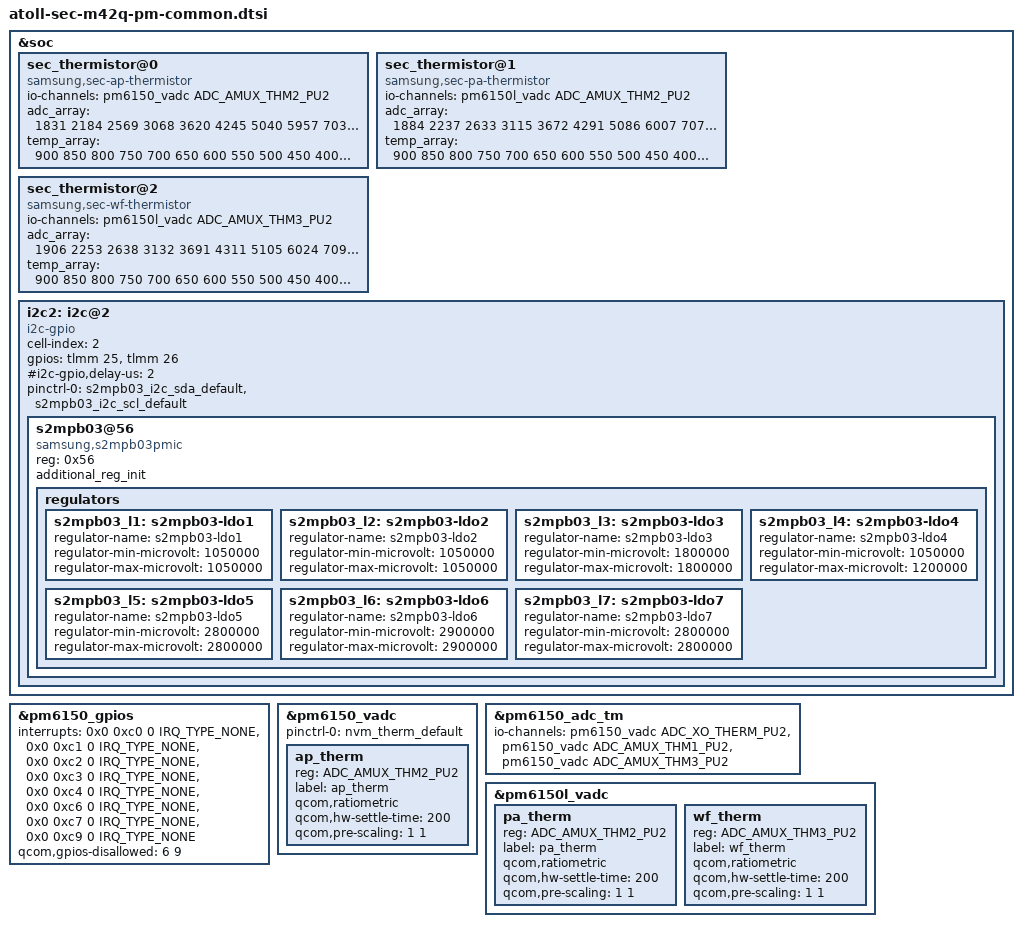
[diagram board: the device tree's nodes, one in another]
/* Copyright (c) 2020, The Linux Foundation. All rights reserved.
 *
 * This program is free software; you can redistribute it and/or modify
 * it under the terms of the GNU General Public License version 2 and
 * only version 2 as published by the Free Software Foundation.
 *
 * This program is distributed in the hope that it will be useful,
 * but WITHOUT ANY WARRANTY; without even the implied warranty of
 * MERCHANTABILITY or FITNESS FOR A PARTICULAR PURPOSE.  See the
 * GNU General Public License for more details.
 */

#include "atoll-sec-pm-common.dtsi"

&soc {
	/* AP Thermistor table */
	sec_thermistor@0 {
		compatible = "samsung,sec-ap-thermistor";
		status = "okay";
		io-channels = <&pm6150_vadc ADC_AMUX_THM2_PU2>;
		io-channel-names = "ap_therm";
		adc_array = <1831 2184 2569 3068 3620 4245 5040
					5957 7030 8198 9474 10919 12557
					14185 15894 17587 19209 20739 22151 23427 24543 25514 26296>;
		temp_array = <900 850 800 750 700 650 600
					550 500 450 400 350 300
					250 200 150 100 50 0 (-50) (-100) (-150) (-200)>;
	};

	/* PA Thermistor table */
	sec_thermistor@1 {
		compatible = "samsung,sec-pa-thermistor";
		status = "okay";
		io-channels = <&pm6150l_vadc ADC_AMUX_THM2_PU2>;
		io-channel-names = "pa_therm";
		adc_array = <1884 2237 2633 3115 3672 4291 5086
					6007 7076 8240 9517 10963 12595
					14223 15931 17618 19239 20769 22189 23458 24574 25535 26323>;
		temp_array = <900 850 800 750 700 650 600
					550 500 450 400 350 300
					250 200 150 100 50 0 (-50) (-100) (-150) (-200)>;
	};

	/* WiFi Thermistor table */
	sec_thermistor@2 {
		compatible = "samsung,sec-wf-thermistor";
		status = "okay";
		io-channels = <&pm6150l_vadc ADC_AMUX_THM3_PU2>;
		io-channel-names = "wf_therm";
		adc_array = <1906 2253 2638 3132 3691 4311 5105
					6024 7093 8255 9536 10982 12611
					14244 15952 17641 19258 20787 22211 23479 24594 25552 26336>;
		temp_array = <900 850 800 750 700 650 600
					550 500 450 400 350 300
					250 200 150 100 50 0 (-50) (-100) (-150) (-200)>;
	};

	/* S2MPB03 Camera PMIC */
	i2c2: i2c@2 {
		cell-index = <2>;
		compatible = "i2c-gpio";
		gpios = <&tlmm 25 0 /* sda */
			&tlmm 26 0 /* scl */
		>;
		#i2c-gpio,delay-us = <2>;
		#address-cells = <1>;
		#size-cells = <0>;

		pinctrl-names = "default";
		pinctrl-0 = <&s2mpb03_i2c_sda_default &s2mpb03_i2c_scl_default>;

		/* S2MPB03 Camera PMIC */
		s2mpb03@56 {
			compatible = "samsung,s2mpb03pmic";
			reg = <0x56>;
			additional_reg_init;

			regulators {
				s2mpb03_l1: s2mpb03-ldo1 {
					regulator-name = "s2mpb03-ldo1";
					regulator-min-microvolt = <1050000>;
					regulator-max-microvolt = <1050000>;
				};

				s2mpb03_l2: s2mpb03-ldo2 {
					regulator-name = "s2mpb03-ldo2";
					regulator-min-microvolt = <1050000>;
					regulator-max-microvolt = <1050000>;
				};

				s2mpb03_l3: s2mpb03-ldo3 {
					regulator-name = "s2mpb03-ldo3";
					regulator-min-microvolt = <1800000>;
					regulator-max-microvolt = <1800000>;
				};

				s2mpb03_l4: s2mpb03-ldo4 {
					regulator-name = "s2mpb03-ldo4";
					regulator-min-microvolt = <1050000>;
					regulator-max-microvolt = <1200000>;
				};

				s2mpb03_l5: s2mpb03-ldo5 {
					regulator-name = "s2mpb03-ldo5";
					regulator-min-microvolt = <2800000>;
					regulator-max-microvolt = <2800000>;
				};

				s2mpb03_l6: s2mpb03-ldo6 {
					regulator-name = "s2mpb03-ldo6";
					regulator-min-microvolt = <2900000>;
					regulator-max-microvolt = <2900000>;
				};

				s2mpb03_l7: s2mpb03-ldo7 {
					regulator-name = "s2mpb03-ldo7";
					regulator-min-microvolt = <2800000>;
					regulator-max-microvolt = <2800000>;
				};
			};
		};
	};
};

&pm6150_gpios {
	interrupts = <0x0 0xc0 0 IRQ_TYPE_NONE>,
		<0x0 0xc1 0 IRQ_TYPE_NONE>,
		<0x0 0xc2 0 IRQ_TYPE_NONE>,
		<0x0 0xc3 0 IRQ_TYPE_NONE>,
		<0x0 0xc4 0 IRQ_TYPE_NONE>,
		<0x0 0xc6 0 IRQ_TYPE_NONE>,
		<0x0 0xc7 0 IRQ_TYPE_NONE>,
		<0x0 0xc9 0 IRQ_TYPE_NONE>;
	interrupt-names = "pm6150_gpio1", "pm6150_gpio2",
		"pm6150_gpio3", "pm6150_gpio4", "pm6150_gpio5",
		"pm6150_gpio7", "pm6150_gpio8",
		"pm6150_gpio10";
	qcom,gpios-disallowed = <6 9>;

	/delete-node/ sdm_skin_therm;
};

&pm6150_vadc {
	pinctrl-0 = <&nvm_therm_default>;

	ap_therm {
		reg = <ADC_AMUX_THM2_PU2>;
		label = "ap_therm";
		qcom,ratiometric;
		qcom,hw-settle-time = <200>;
		qcom,pre-scaling = <1 1>;
	};

	/delete-node/ sdm_skin_therm;
};

&pm6150_adc_tm {
	io-channels = <&pm6150_vadc ADC_XO_THERM_PU2>,
			<&pm6150_vadc ADC_AMUX_THM1_PU2>,
			<&pm6150_vadc ADC_AMUX_THM3_PU2>;

	/delete-node/ sdm_skin_therm;
};

&pm6150l_vadc {
	/delete-node/ pa_therm0;

	pa_therm {
		reg = <ADC_AMUX_THM2_PU2>;
		label = "pa_therm";
		qcom,ratiometric;
		qcom,hw-settle-time = <200>;
		qcom,pre-scaling = <1 1>;
	};

	wf_therm {
		reg = <ADC_AMUX_THM3_PU2>;
		label = "wf_therm";
		qcom,ratiometric;
		qcom,hw-settle-time = <200>;
		qcom,pre-scaling = <1 1>;
	};
};
